# LargeDummyDevice register map
File version: 1.0
Registers are 32-bit, read-write, no defined reset value unless marked. A register's access mark holds for its fields unless they carry their own. Offsets are from the block's base; [hi:lo] are bit positions.

## PERIPHERAL_34
Base 0x40021000
0x04 REG_1 — Register 1
  [31:29] FIELD_7, [28:26] FIELD_3, [28:24] FIELD_4, [25:24] FIELD_6, [18] FIELD_1, [18:15] FIELD_5, [12:11] FIELD_2
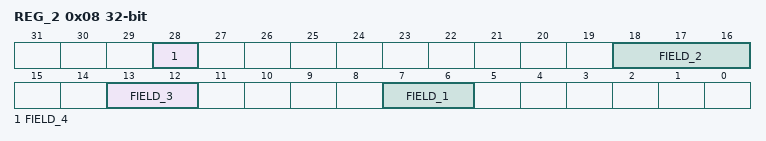
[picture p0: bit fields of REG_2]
0x08 REG_2 — Register 2
  [28] FIELD_4, [18:16] FIELD_2, [13:12] FIELD_3, [7:6] FIELD_1
0x0C REG_3 — Register 3
  [31:29] FIELD_2, [30:29] FIELD_11, [31:28] FIELD_1, [23] FIELD_14, [22:20] FIELD_6, [14] FIELD_4, [17:14] FIELD_5, [12:11] FIELD_7, [9] FIELD_3, [11:9] FIELD_10, [8:6] FIELD_9, [5:3] FIELD_12, [1:0] FIELD_8, [3:0] FIELD_13
0x10 REG_4 — Register 4
  [35:31] FIELD_21, [30] FIELD_15, [31:28] FIELD_3, [29:28] FIELD_13, [26] FIELD_17, [28:25] FIELD_12, [23:22] FIELD_8, [24:21] FIELD_5, [22:21] FIELD_22, [22:20] FIELD_11, [23:20] FIELD_20, [22:19] FIELD_7, [20:18] FIELD_2, [19:15] FIELD_9, [17:13] FIELD_16, [11:10] FIELD_10, [7] FIELD_18, [6:4] FIELD_14, [5:3] FIELD_19, [3:2] FIELD_6, [0] FIELD_1, [3:0] FIELD_4
0x14 REG_5 — Register 5
  [31] FIELD_6, [35:31] FIELD_16, [28:27] FIELD_12, [28:25] FIELD_22, [28:24] FIELD_9, [24] FIELD_10, [24:23] FIELD_18, [26:22] FIELD_20, [21] FIELD_11, [24:20] FIELD_19, [22:20] FIELD_26, [19] FIELD_4, [18] FIELD_15, [17] FIELD_17, [19:16] FIELD_14, [18:16] FIELD_27, [18:15] FIELD_3, [14:11] FIELD_2, [11:10] FIELD_5, [9:8] FIELD_8, [12:8] FIELD_28, [11:7] FIELD_1, [8:6] FIELD_21, [8:6] FIELD_25, [5] FIELD_23, [3] FIELD_7, [4:3] FIELD_24, [3:0] FIELD_13
0x18 REG_6 — Register 6
  [35:31] FIELD_19, [30:28] FIELD_3, [29:28] FIELD_21, [28:26] FIELD_20, [22:21] FIELD_13, [25:21] FIELD_17, [20] FIELD_9, [22:18] FIELD_22, [16:12] FIELD_8, [15:11] FIELD_18, [13:9] FIELD_12, [11:9] FIELD_14, [12:9] FIELD_16, [9:8] FIELD_11, [7] FIELD_1, [6:5] FIELD_2, [3] FIELD_5, [5:3] FIELD_7, [5:2] FIELD_4, [4:2] FIELD_10, [3:2] FIELD_15, [5:1] FIELD_6
0x1C REG_7 — Register 7
  [31:30] FIELD_9, [33:30] FIELD_26, [34:30] FIELD_27, [27] FIELD_14, [22] FIELD_11, [24:21] FIELD_28, [21:20] FIELD_17, [23:20] FIELD_24, [21:19] FIELD_5, [20:19] FIELD_8, [22:18] FIELD_22, [15] FIELD_10, [18:14] FIELD_21, [14:12] FIELD_3, [12] FIELD_20, [11:10] FIELD_19, [14:10] FIELD_23, [8] FIELD_15, [12:8] FIELD_16, [7] FIELD_2, [9:6] FIELD_7, [9:6] FIELD_13, [5] FIELD_1, [8:5] FIELD_18, [7:4] FIELD_29, [5:3] FIELD_4, [5:3] FIELD_25, [1] FIELD_6, [5:1] FIELD_12
0x20 REG_8 — Register 8
  [32:31] FIELD_17, [31] FIELD_21, [34:31] FIELD_22, [32:30] FIELD_23, [28:26] FIELD_4, [27:26] FIELD_14, [29:25] FIELD_18, [24:21] FIELD_13, [23:20] FIELD_8, [24:20] FIELD_24, [22:19] FIELD_16, [19] FIELD_19, [19:17] FIELD_11, [18:16] FIELD_2, [20:16] FIELD_9, [13] FIELD_1, [13] FIELD_3, [12:10] FIELD_6, [8] FIELD_12, [7:5] FIELD_15, [7:4] FIELD_7, [6:3] FIELD_20, [4:1] FIELD_10, [3:0] FIELD_5
0x24 REG_9 — Register 9
  [29:28] FIELD_9, [31:27] FIELD_5, [28:24] FIELD_7, [25:22] FIELD_3, [21] FIELD_4, [20] FIELD_6, [21:18] FIELD_2, [18] FIELD_10, [22:18] FIELD_11, [15:13] FIELD_8, [12:10] FIELD_1
0x28 REG_10 — Register 10
  [33:29] FIELD_23, [29:26] FIELD_3, [28:26] FIELD_6, [26] FIELD_12, [25:22] FIELD_16, [22:21] FIELD_5, [23:21] FIELD_9, [22:18] FIELD_2, [19:18] FIELD_20, [16] FIELD_10, [17:16] FIELD_11, [18:15] FIELD_7, [16:14] FIELD_8, [17:13] FIELD_13, [16:12] FIELD_15, [13:12] FIELD_18, [11] FIELD_1, [13:11] FIELD_4, [9:7] FIELD_22, [7:6] FIELD_24, [7:5] FIELD_17, [7:5] FIELD_21, [6:2] FIELD_19, [3:0] FIELD_14
0x2C REG_11 — Register 11
  [32:31] FIELD_23, [29:28] FIELD_8, [31:27] FIELD_19, [29:25] FIELD_2, [27:25] FIELD_5, [25] FIELD_18, [25:24] FIELD_1, [24:22] FIELD_9, [21:20] FIELD_7, [20:19] FIELD_11, [20:18] FIELD_10, [19:17] FIELD_6, [16:14] FIELD_3, [14:11] FIELD_15, [9] FIELD_17, [9:8] FIELD_4, [9:7] FIELD_12, [8:7] FIELD_20, [10:7] FIELD_21, [4] FIELD_22, [4:1] FIELD_13, [4:0] FIELD_14, [0] FIELD_16
